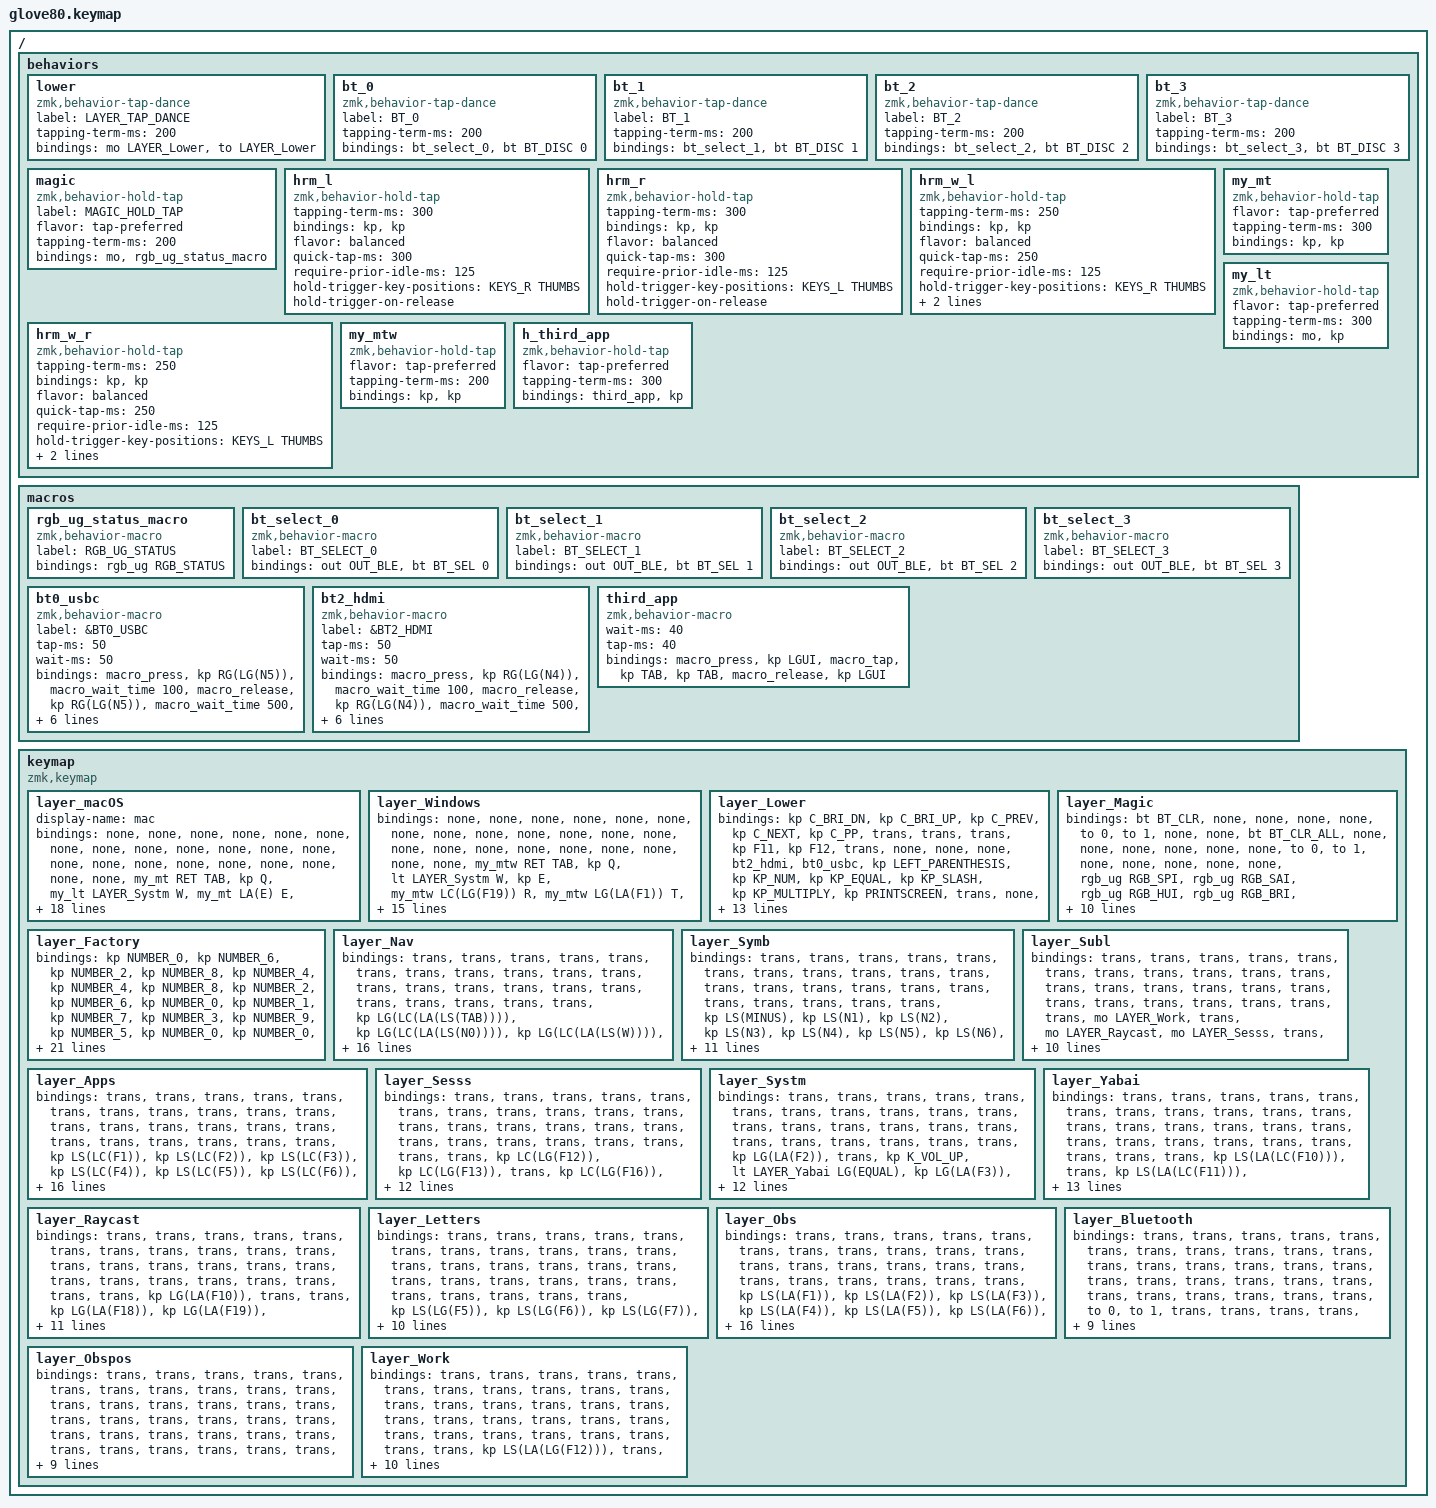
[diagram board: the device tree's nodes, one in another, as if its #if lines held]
/*
 * Copyright (c) 2020 The ZMK Contributors
 * Copyright (c) 2023 Innaworks Development Limited, trading as MoErgo
 *
 * SPDX-License-Identifier: MIT
 */


/* THIS FILE WAS GENERATED BY GLOVE80 LAYOUT EDITOR
 *
 * This file was generated automatically. You may or may not want to
 * edit it directly.
 */

#include <behaviors.dtsi>
/* Include all behavior includes needed */
#include <dt-bindings/zmk/outputs.h>
#include <dt-bindings/zmk/keys.h>
#include <dt-bindings/zmk/bt.h>
#include <dt-bindings/zmk/rgb.h>

/* On demand includes */


/* Automatically generated layer name #define */
#define LAYER_macOS 0
#define LAYER_Windows 1
#define LAYER_Lower 2
#define LAYER_Magic 3
#define LAYER_Factory 4
#define LAYER_Nav 5
#define LAYER_Symb 6
#define LAYER_Subl 7
#define LAYER_Apps 8
#define LAYER_Sesss 9
#define LAYER_Systm 10
#define LAYER_Yabai 11
#define LAYER_Raycast 12
#define LAYER_Letters 13
#define LAYER_Obs 14
#define LAYER_Bluetooth 15
#define LAYER_Obspos 16
#define LAYER_Work 17

/* To deal with the situation where there is no Lower layer, to keep &lower happy */
#ifndef LAYER_Lower
#define LAYER_Lower 0
#endif

/* Custom Device-tree */



/* Glove80 system behavior & macros */
/ {
    behaviors {
        // For the "layer" key, it'd nice to be able to use it as either a shift or a toggle.
        // Configure it as a tap dance, so the first tap (or hold) is a &mo and the second tap is a &to
        lower: lower {
            compatible = "zmk,behavior-tap-dance";
            label = "LAYER_TAP_DANCE";
            #binding-cells = <0>;
            tapping-term-ms = <200>;
            bindings = <&mo LAYER_Lower>, <&to LAYER_Lower>;
        };
    };
};

/ {
    macros {
        rgb_ug_status_macro: rgb_ug_status_macro {
            label = "RGB_UG_STATUS";
            compatible = "zmk,behavior-macro";
            #binding-cells = <0>;
            bindings
                = <&rgb_ug RGB_STATUS>;
        };
    };
};


/ {
#ifdef BT_DISC_CMD
    behaviors {
        bt_0: bt_0 {
            compatible = "zmk,behavior-tap-dance";
            label = "BT_0";
            #binding-cells = <0>;
            tapping-term-ms = <200>;
            bindings = <&bt_select_0>, <&bt BT_DISC 0>;
        };
        bt_1: bt_1 {
            compatible = "zmk,behavior-tap-dance";
            label = "BT_1";
            #binding-cells = <0>;
            tapping-term-ms = <200>;
            bindings = <&bt_select_1>, <&bt BT_DISC 1>;
        };
        bt_2: bt_2 {
            compatible = "zmk,behavior-tap-dance";
            label = "BT_2";
            #binding-cells = <0>;
            tapping-term-ms = <200>;
            bindings = <&bt_select_2>, <&bt BT_DISC 2>;
        };
        bt_3: bt_3 {
            compatible = "zmk,behavior-tap-dance";
            label = "BT_3";
            #binding-cells = <0>;
            tapping-term-ms = <200>;
            bindings = <&bt_select_3>, <&bt BT_DISC 3>;
        };
    };
    macros {
        bt_select_0: bt_select_0 {
            label = "BT_SELECT_0";
            compatible = "zmk,behavior-macro";
            #binding-cells = <0>;
            bindings
                = <&out OUT_BLE>,
                  <&bt BT_SEL 0>;
        };
        bt_select_1: bt_select_1 {
            label = "BT_SELECT_1";
            compatible = "zmk,behavior-macro";
            #binding-cells = <0>;
            bindings
                = <&out OUT_BLE>,
                  <&bt BT_SEL 1>;
        };
        bt_select_2: bt_select_2 {
            label = "BT_SELECT_2";
            compatible = "zmk,behavior-macro";
            #binding-cells = <0>;
            bindings
                = <&out OUT_BLE>,
                  <&bt BT_SEL 2>;
        };
        bt_select_3: bt_select_3 {
            label = "BT_SELECT_3";
            compatible = "zmk,behavior-macro";
            #binding-cells = <0>;
            bindings
                = <&out OUT_BLE>,
                  <&bt BT_SEL 3>;
        };
    };
#else
    macros {
        bt_0: bt_0 {
            label = "BT_0";
            compatible = "zmk,behavior-macro";
            #binding-cells = <0>;
            bindings
                = <&out OUT_BLE>,
                  <&bt BT_SEL 0>;
        };
        bt_1: bt_1 {
            label = "BT_1";
            compatible = "zmk,behavior-macro";
            #binding-cells = <0>;
            bindings
                = <&out OUT_BLE>,
                  <&bt BT_SEL 1>;
        };
        bt_2: bt_2 {
            label = "BT_2";
            compatible = "zmk,behavior-macro";
            #binding-cells = <0>;
            bindings
                = <&out OUT_BLE>,
                  <&bt BT_SEL 2>;
        };
        bt_3: bt_3 {
            label = "BT_3";
            compatible = "zmk,behavior-macro";
            #binding-cells = <0>;
            bindings
                = <&out OUT_BLE>,
                  <&bt BT_SEL 3>;
        };
    };
#endif
};

/ {
    behaviors {
        magic: magic {
            compatible = "zmk,behavior-hold-tap";
            label = "MAGIC_HOLD_TAP";
            #binding-cells = <2>;
            flavor = "tap-preferred";
            tapping-term-ms = <200>;
            bindings = <&mo>, <&rgb_ug_status_macro>;
        };
    };
};

/* #define for key positions */
#define POS_LH_T1 52
#define POS_LH_T2 53
#define POS_LH_T3 54
#define POS_LH_T4 69
#define POS_LH_T5 70
#define POS_LH_T6 71
#define POS_LH_C1R2 15
#define POS_LH_C1R3 27
#define POS_LH_C1R4 39
#define POS_LH_C1R5 51
#define POS_LH_C2R1 4
#define POS_LH_C2R2 14
#define POS_LH_C2R3 26
#define POS_LH_C2R4 38
#define POS_LH_C2R5 50
#define POS_LH_C2R6 68
#define POS_LH_C3R1 3
#define POS_LH_C3R2 13
#define POS_LH_C3R3 25
#define POS_LH_C3R4 37
#define POS_LH_C3R5 49
#define POS_LH_C3R6 67
#define POS_LH_C4R1 2
#define POS_LH_C4R2 12
#define POS_LH_C4R3 24
#define POS_LH_C4R4 36
#define POS_LH_C4R5 48
#define POS_LH_C4R6 66
#define POS_LH_C5R1 1
#define POS_LH_C5R2 11
#define POS_LH_C5R3 23
#define POS_LH_C5R4 35
#define POS_LH_C5R5 47
#define POS_LH_C5R6 65
#define POS_LH_C6R1 0
#define POS_LH_C6R2 10
#define POS_LH_C6R3 22
#define POS_LH_C6R4 34
#define POS_LH_C6R5 46
#define POS_LH_C6R6 64
#define POS_RH_T1 57
#define POS_RH_T2 56
#define POS_RH_T3 55
#define POS_RH_T4 74
#define POS_RH_T5 73
#define POS_RH_T6 72
#define POS_RH_C1R2 16
#define POS_RH_C1R3 28
#define POS_RH_C1R4 40
#define POS_RH_C1R5 58
#define POS_RH_C2R1 5
#define POS_RH_C2R2 17
#define POS_RH_C2R3 29
#define POS_RH_C2R4 41
#define POS_RH_C2R5 59
#define POS_RH_C2R6 75
#define POS_RH_C3R1 6
#define POS_RH_C3R2 18
#define POS_RH_C3R3 30
#define POS_RH_C3R4 42
#define POS_RH_C3R5 60
#define POS_RH_C3R6 76
#define POS_RH_C4R1 7
#define POS_RH_C4R2 19
#define POS_RH_C4R3 31
#define POS_RH_C4R4 43
#define POS_RH_C4R5 61
#define POS_RH_C4R6 77
#define POS_RH_C5R1 8
#define POS_RH_C5R2 20
#define POS_RH_C5R3 32
#define POS_RH_C5R4 44
#define POS_RH_C5R5 62
#define POS_RH_C5R6 78
#define POS_RH_C6R1 9
#define POS_RH_C6R2 21
#define POS_RH_C6R3 33
#define POS_RH_C6R4 45
#define POS_RH_C6R5 63
#define POS_RH_C6R6 79

#define KEYS_L 22 23 24 25 26 27 34 35 36 37 38 39 46 47 48 49 50 51
#define KEYS_R 28 29 30 31 32 33 40 41 42 43 44 45 58 59 60 61 62 63
#define THUMBS 69 70 73 74

/* Custom Defined Behaviors */
/ {
    macros {
        bt0_usbc: bt0_usbc {
            label = "&BT0_USBC";
            compatible = "zmk,behavior-macro";
            #binding-cells = <0>;
            tap-ms = <50>;
            wait-ms = <50>;
            bindings
                /* switch mouse */
                = <&macro_press>
                , <&kp RG(LG(N5))>
                , <&macro_wait_time 100>
                , <&macro_release>
                , <&kp RG(LG(N5))>
                , <&macro_wait_time 500>
                /* switch input source monitor */
                , <&macro_press>
                , <&kp LC(LA(LS(LG(N5))))>
                , <&macro_release>
                , <&kp LC(LA(LS(LG(N5))))>
                , <&macro_wait_time 50>
                /* pull github repos */
                , <&macro_press>
                , <&kp RG(LG(J))>
                , <&macro_release>
                , <&kp RG(LG(J))>
                , <&macro_wait_time 50>
                /* switch keyboard */
                , <&macro_press>
                , <&bt_0>
                , <&macro_release>
                , <&bt_0>;
        };
        bt2_hdmi: bt2_hdmi {
            label = "&BT2_HDMI";
            compatible = "zmk,behavior-macro";
            #binding-cells = <0>;
            tap-ms = <50>;
            wait-ms = <50>;
            bindings
                /* switch mouse */
                = <&macro_press>
                , <&kp RG(LG(N4))>
                , <&macro_wait_time 100>
                , <&macro_release>
                , <&kp RG(LG(N4))>
                , <&macro_wait_time 500>
                /* switch input source monitor */
                , <&macro_press>
                , <&kp LC(LA(LS(LG(N4))))>
                , <&macro_release>
                , <&kp LC(LA(LS(LG(N4))))>
                , <&macro_wait_time 50>
                /* pull github repos */
                , <&macro_press>
                , <&kp RG(LG(J))>
                , <&macro_release>
                , <&kp RG(LG(J))>
                , <&macro_wait_time 50>
                /* switch keyboard */
                , <&macro_press>
                , <&bt_2>
                , <&macro_release>
                , <&bt_2>;
        };
    };
};

/* Automatically generated macro definitions */
/ {
    macros {
        third_app: third_app {
            compatible = "zmk,behavior-macro";
            #binding-cells = <0>;
            wait-ms = <40>;
            tap-ms = <40>;
            bindings
                = <&macro_press &kp LGUI>
                , <&macro_tap &kp TAB &kp TAB>
                , <&macro_release &kp LGUI>
                ;
        };

    };
};

/* Automatically generated behavior definitions */
/ {
    behaviors {
        // Timeless home-row mods, adapted from the Toucan keymap.
        hrm_l: hrm_l {
            compatible = "zmk,behavior-hold-tap";
            #binding-cells = <2>;
            tapping-term-ms = <300>;
            bindings = <&kp>, <&kp>;
            flavor = "balanced";
            quick-tap-ms = <300>;
            require-prior-idle-ms = <125>;
            hold-trigger-key-positions = <KEYS_R THUMBS>;
            hold-trigger-on-release;
        };

        hrm_r: hrm_r {
            compatible = "zmk,behavior-hold-tap";
            #binding-cells = <2>;
            tapping-term-ms = <300>;
            bindings = <&kp>, <&kp>;
            flavor = "balanced";
            quick-tap-ms = <300>;
            require-prior-idle-ms = <125>;
            hold-trigger-key-positions = <KEYS_L THUMBS>;
            hold-trigger-on-release;
        };

        hrm_w_l: hrm_w_l {
            compatible = "zmk,behavior-hold-tap";
            #binding-cells = <2>;
            tapping-term-ms = <250>;
            bindings = <&kp>, <&kp>;
            flavor = "balanced";
            quick-tap-ms = <250>;
            require-prior-idle-ms = <125>;
            hold-trigger-key-positions = <KEYS_R THUMBS>;
            hold-trigger-on-release;
            retro-tap;
        };

        hrm_w_r: hrm_w_r {
            compatible = "zmk,behavior-hold-tap";
            #binding-cells = <2>;
            tapping-term-ms = <250>;
            bindings = <&kp>, <&kp>;
            flavor = "balanced";
            quick-tap-ms = <250>;
            require-prior-idle-ms = <125>;
            hold-trigger-key-positions = <KEYS_L THUMBS>;
            hold-trigger-on-release;
            retro-tap;
        };

        my_mt: my_mt {
            compatible = "zmk,behavior-hold-tap";
            #binding-cells = <2>;
            flavor = "tap-preferred";
            tapping-term-ms = <300>;
            bindings = <&kp>, <&kp>;
        };

        my_lt: my_lt {
            compatible = "zmk,behavior-hold-tap";
            #binding-cells = <2>;
            flavor = "tap-preferred";
            tapping-term-ms = <300>;
            bindings = <&mo>, <&kp>;
        };

        my_mtw: my_mtw {
            compatible = "zmk,behavior-hold-tap";
            #binding-cells = <2>;
            flavor = "tap-preferred";
            tapping-term-ms = <200>;
            bindings = <&kp>, <&kp>;
        };

        h_third_app: h_third_app {
            compatible = "zmk,behavior-hold-tap";
            #binding-cells = <2>;
            flavor = "tap-preferred";
            tapping-term-ms = <300>;
            bindings = <&third_app>, <&kp>;
        };

        /* symbl: symbl { */
        /*     compatible = "zmk,behavior-hold-tap"; */
        /*     #binding-cells = <2>; */
        /*     flavor = "tap-preferred"; */
        /*     tapping-term-ms = <300>; */
        /*     bindings = <&mo>, <&kp>; */
        /*     display-name = "Symbol-Layer"; */
        /* }; */

    };
};

/* Automatically generated combos definitions */


/* Automatically generated keymap */
/ {
    keymap {
        compatible = "zmk,keymap";


        layer_macOS {
            display-name = "mac";
            bindings = <
//    ┌────────────────────────┬────────────────────┬────────────────────────┬──────────────────┬──────────────────────────┐                                                                                                                     ┌─────────────────────────┬───────────────┬────────────────────────────────────┬───────────────┬─────┐
//    │                        │                    │                        │                  │                          │                                                                                                                     │                         │               │                                    │               │     │
//    ├────────────────────────┼────────────────────┼────────────────────────┼──────────────────┼──────────────────────────┼─────────────────────────┐                                                                        ┌──────────────────┼─────────────────────────┼───────────────┼────────────────────────────────────┼───────────────┼─────┤
//    │                        │                    │                        │                  │                          │                         │                                                                        │                  │                         │               │                                    │               │     │
//    ├────────────────────────┼────────────────────┼────────────────────────┼──────────────────┼──────────────────────────┼─────────────────────────┤                                                                        ├──────────────────┼─────────────────────────┼───────────────┼────────────────────────────────────┼───────────────┼─────┤
//    │     &my_mt ent tab     │         Q          │ &my_lt laltYER_Systm W │ &my_mt lalt(E) E │ &my_mt lctl(lgui(f19)) R │ &my_mt lgui(lalt(f1)) T │                                                                        │        Y         │    &my_mt lgui(Z) U     │       I       │ &my_mt lgui(lctl(lalt(lsft(Z)))) O │       P       │  \  │
//    ├────────────────────────┼────────────────────┼────────────────────────┼──────────────────┼──────────────────────────┼─────────────────────────┤                                                                        ├──────────────────┼─────────────────────────┼───────────────┼────────────────────────────────────┼───────────────┼─────┤
//    │   lt laltYER_Nav esc   │   &hrm_l lctl A    │     &hrm_l lsft S      │  &hrm_l lalt D   │      &hrm_l lgui F       │    &my_mt lctl(Z) G     │                                                                        │ &h_third_app 0 H │      &hrm_r rgui J      │ &hrm_r ralt K │           &hrm_r rsft L            │ &hrm_r rctl ; │  '  │
//    ├────────────────────────┼────────────────────┼────────────────────────┼──────────────────┼──────────────────────────┼─────────────────────────┼──────────────────────┬─────┬─────┐   ┌─────┬─────┬─────────────────────┼──────────────────┼─────────────────────────┼───────────────┼────────────────────────────────────┼───────────────┼─────┤
//    │                        │ &my_mt lgui(tab) Z │    &my_mt lgui(`) X    │ &my_mt lgui(C) C │     &my_mt lgui(V) V     │ &my_mt lgui(lalt(f8)) B │                      │     │     │   │     │     │                     │ &my_mt lalt(N) N │ &my_mt lgui(lalt(f9)) M │       ,       │ &my_mt lgui(lctl(lalt(lsft(6)))) . │       /       │     │
//    ├────────────────────────┼────────────────────┼────────────────────────┼──────────────────┼──────────────────────────┼─────────────────────────┼──────────────────────┼─────┼─────┤   ├─────┼─────┼─────────────────────┼──────────────────┼─────────────────────────┼───────────────┼────────────────────────────────────┼───────────────┼─────┤
//    │ &magic laltYER_Magic 0 │                    │                        │                  │                          │                         │ lt laltYER_Symb bspc │ spc │     │   │     │ spc │ lt laltYER_Subl ent │                  │                         │               │                                    │               │     │
//    └────────────────────────┴────────────────────┴────────────────────────┴──────────────────┴──────────────────────────┘                         └──────────────────────┴─────┴─────┘   └─────┴─────┴─────────────────────┘                  └─────────────────────────┴───────────────┴────────────────────────────────────┴───────────────┴─────┘
  &none                  &none              &none                  &none            &none                                                                                                                                                  &none                 &none           &none                          &none               &none
  &none                  &none              &none                  &none            &none                  &none                                                                                                        &none              &none                 &none           &none                          &none               &none
  &my_mt RET TAB         &kp Q              &my_lt LAYER_Systm W   &my_mt LA(E) E   &my_mt LC(LG(F19)) R   &my_mt LG(LA(F1)) T                                                                                          &kp Y              &my_mt LG(Z) U        &kp I           &my_mt LG(LC(LA(LS(Z)))) O     &kp P               &kp BSLH
  &lt LAYER_Nav ESC      &hrm_l LCTRL A     &hrm_l LSHFT S         &hrm_l LALT D    &hrm_l LGUI F          &my_mt LC(Z) G                                                                                               &h_third_app 0 H   &hrm_r RGUI J         &hrm_r RALT K   &hrm_r RSHFT L                 &hrm_r RCTRL SEMI   &kp SQT
  &none                  &my_mt LG(TAB) Z   &my_mt LG(GRAVE) X     &my_mt LG(C) C   &my_mt LG(V) V         &my_mt LG(LA(F8)) B   &none                 &none       &none       &none   &none       &none                &my_mt LA(N) N     &my_mt LG(LA(F9)) M   &kp COMMA       &my_mt LG(LC(LA(LS(6)))) DOT   &kp FSLH            &none
  &magic LAYER_Magic 0   &none              &none                  &none            &none                                        &lt LAYER_Symb BSPC   &kp SPACE   &none       &none   &kp SPACE   &lt LAYER_Subl RET                      &none                 &none           &none                          &none               &none
            >;
        };


        layer_Windows {
            bindings = <
//    ┌────────────────────────┬────────────────────────────────┬────────────────────────────────┬───────────────────┬───────────────────────────┐                                                                                                         ┌──────────────────┬─────────────────┬─────────────────┬─────────────────┬─────┐
//    │                        │                                │                                │                   │                           │                                                                                                         │                  │                 │                 │                 │     │
//    ├────────────────────────┼────────────────────────────────┼────────────────────────────────┼───────────────────┼───────────────────────────┼──────────────────────────┐                                                                        ┌─────┼──────────────────┼─────────────────┼─────────────────┼─────────────────┼─────┤
//    │                        │                                │                                │                   │                           │                          │                                                                        │     │                  │                 │                 │                 │     │
//    ├────────────────────────┼────────────────────────────────┼────────────────────────────────┼───────────────────┼───────────────────────────┼──────────────────────────┤                                                                        ├─────┼──────────────────┼─────────────────┼─────────────────┼─────────────────┼─────┤
//    │    &my_mtw ent tab     │               Q                │       lt laltYER_Systm W       │         E         │ &my_mtw lctl(lgui(f19)) R │ &my_mtw lgui(lalt(f1)) T │                                                                        │  Y  │ &my_mt lctl(Z) U │        I        │        O        │        P        │  \  │
//    ├────────────────────────┼────────────────────────────────┼────────────────────────────────┼───────────────────┼───────────────────────────┼──────────────────────────┤                                                                        ├─────┼──────────────────┼─────────────────┼─────────────────┼─────────────────┼─────┤
//    │   lt laltYER_Nav esc   │        &hrm_w_l lctl A         │        &hrm_w_l lsft S         │  &hrm_w_l lgui D  │      &hrm_w_l lalt F      │            G             │                                                                        │  H  │ &hrm_w_r ralt J  │ &hrm_w_r rgui K │ &hrm_w_r rsft L │ &hrm_w_r rctl ; │  '  │
//    ├────────────────────────┼────────────────────────────────┼────────────────────────────────┼───────────────────┼───────────────────────────┼──────────────────────────┼──────────────────────┬─────┬─────┐   ┌─────┬─────┬─────────────────────┼─────┼──────────────────┼─────────────────┼─────────────────┼─────────────────┼─────┤
//    │                        │ &my_mtw lsft(lalt(lgui(f6))) Z │ &my_mtw lsft(lalt(lgui(f7))) X │ &my_mtw lctl(C) C │     &my_mtw lctl(V) V     │            B             │                      │     │     │   │     │     │                     │  N  │        M         │        ,        │        .        │        /        │     │
//    ├────────────────────────┼────────────────────────────────┼────────────────────────────────┼───────────────────┼───────────────────────────┼──────────────────────────┼──────────────────────┼─────┼─────┤   ├─────┼─────┼─────────────────────┼─────┼──────────────────┼─────────────────┼─────────────────┼─────────────────┼─────┤
//    │ &magic laltYER_Magic 0 │                                │                                │                   │                           │                          │ lt laltYER_Symb bspc │ spc │     │   │     │ spc │ lt laltYER_Subl ent │     │                  │                 │                 │                 │     │
//    └────────────────────────┴────────────────────────────────┴────────────────────────────────┴───────────────────┴───────────────────────────┘                          └──────────────────────┴─────┴─────┘   └─────┴─────┴─────────────────────┘     └──────────────────┴─────────────────┴─────────────────┴─────────────────┴─────┘
  &none                  &none                      &none                      &none             &none                                                                                                                                         &none             &none             &none              &none                 &none
  &none                  &none                      &none                      &none             &none                   &none                                                                                                         &none   &none             &none             &none              &none                 &none
  &my_mtw RET TAB        &kp Q                      &lt LAYER_Systm W          &kp E             &my_mtw LC(LG(F19)) R   &my_mtw LG(LA(F1)) T                                                                                          &kp Y   &my_mt LC(Z) U    &kp I             &kp O              &kp P                 &kp BSLH
  &lt LAYER_Nav ESC      &hrm_w_l LCTRL A           &hrm_w_l LSHFT S           &hrm_w_l LGUI D   &hrm_w_l LALT F         &kp G                                                                                                         &kp H   &hrm_w_r RALT J   &hrm_w_r RGUI K   &hrm_w_r RSHFT L   &hrm_w_r RCTRL SEMI   &kp SQT
  &none                  &my_mtw LS(LA(LG(F6))) Z   &my_mtw LS(LA(LG(F7))) X   &my_mtw LC(C) C   &my_mtw LC(V) V         &kp B                  &none                 &none       &none       &none   &none       &none                &kp N   &kp M             &kp COMMA         &kp DOT            &kp FSLH              &none
  &magic LAYER_Magic 0   &none                      &none                      &none             &none                                          &lt LAYER_Symb BSPC   &kp SPACE   &none       &none   &kp SPACE   &lt LAYER_Subl RET           &none             &none             &none              &none                 &none
            >;
        };

        layer_Lower {
            bindings = <
//    ┌────────────────────────┬──────┬──────┬──────┬───────────┐                                                       ┌──────┬──────┬──────┬──────┬──────┐
//    │          bri-          │ bri+ │ prev │ next │   play    │                                                       │      │      │      │ f11  │ f12  │
//    ├────────────────────────┼──────┼──────┼──────┼───────────┼───────────┐                                       ┌───┼──────┼──────┼──────┼──────┼──────┤
//    │                        │      │      │      │ &bt2_hdmi │ &bt0_usbc │                                       │ ( │ nlck │ kp_= │ kp_/ │ kp_* │ pscr │
//    ├────────────────────────┼──────┼──────┼──────┼───────────┼───────────┤                                       ├───┼──────┼──────┼──────┼──────┼──────┤
//    │                        │      │      │  up  │           │    end    │                                       │ ) │  7   │  8   │  9   │ kp_- │ slck │
//    ├────────────────────────┼──────┼──────┼──────┼───────────┼───────────┤                                       ├───┼──────┼──────┼──────┼──────┼──────┤
//    │                        │      │ left │ down │   rght    │    ent    │                                       │ % │  4   │  5   │  6   │ kp_+ │      │
//    ├────────────────────────┼──────┼──────┼──────┼───────────┼───────────┼─────┬─────┬─────┐   ┌─────┬─────┬─────┼───┼──────┼──────┼──────┼──────┼──────┤
//    │                        │ app  │      │      │           │   pgdn    │     │     │     │   │     │     │     │ , │  1   │  2   │  3   │ ent  │      │
//    ├────────────────────────┼──────┼──────┼──────┼───────────┼───────────┼─────┼─────┼─────┤   ├─────┼─────┼─────┼───┼──────┼──────┼──────┼──────┼──────┤
//    │ &magic laltYER_Magic 0 │ caps │ ins  │ f11  │    f12    │           │     │     │     │   │     │     │     │   │  0   │  0   │ kp_. │ ent  │      │
//    └────────────────────────┴──────┴──────┴──────┴───────────┘           └─────┴─────┴─────┘   └─────┴─────┴─────┘   └──────┴──────┴──────┴──────┴──────┘
  &kp C_BRI_DN           &kp C_BRI_UP   &kp C_PREV       &kp C_NEXT       &kp C_PP                                                                                                  &trans       &trans         &trans         &kp F11           &kp F12
  &trans                 &none          &none            &none            &bt2_hdmi   &bt0_usbc                                                             &kp LEFT_PARENTHESIS    &kp KP_NUM   &kp KP_EQUAL   &kp KP_SLASH   &kp KP_MULTIPLY   &kp PRINTSCREEN
  &trans                 &none          &none            &kp UP_ARROW     &none       &kp END                                                               &kp RIGHT_PARENTHESIS   &kp KP_N7    &kp KP_N8      &kp KP_N9      &kp KP_MINUS      &kp SCROLLLOCK
  &trans                 &none          &kp LEFT_ARROW   &kp DOWN_ARROW   &kp RIGHT   &kp RET                                                               &kp PERCENT             &kp KP_N4    &kp KP_N5      &kp KP_N6      &kp KP_PLUS       &none
  &trans                 &kp K_APP      &trans           &trans           &trans      &kp PG_DN   &trans   &trans   &trans       &trans   &trans   &trans   &kp COMMA               &kp KP_N1    &kp KP_N2      &kp KP_N3      &kp KP_ENTER      &trans
  &magic LAYER_Magic 0   &kp CAPS       &kp INS          &kp F11          &kp F12                 &trans   &trans   &trans       &trans   &trans   &trans                           &kp KP_N0    &kp KP_N0      &kp KP_DOT     &kp KP_ENTER      &trans
            >;
        };

        layer_Magic {
            bindings = <
//    ┌────────────┬─────────┬─────────┬─────────┬─────────┐                                                                 ┌──────┬──────┬─────┬─────┬────────────┐
//    │   bt_clr   │         │         │         │         │                                                                 │ to 0 │ to 1 │     │     │ bt_clr_ALL │
//    ├────────────┼─────────┼─────────┼─────────┼─────────┼─────────┐                                                ┌──────┼──────┼──────┼─────┼─────┼────────────┤
//    │            │         │         │         │         │         │                                                │ to 0 │ to 1 │      │     │     │            │
//    ├────────────┼─────────┼─────────┼─────────┼─────────┼─────────┤                                                ├──────┼──────┼──────┼─────┼─────┼────────────┤
//    │            │ ug_ sp+ │ ug_ sa+ │ ug_ hu+ │ ug_ br+ │ ug_ tog │                                                │      │      │      │     │     │            │
//    ├────────────┼─────────┼─────────┼─────────┼─────────┼─────────┤                                                ├──────┼──────┼──────┼─────┼─────┼────────────┤
//    │    boot    │ ug_ sp- │ ug_ sa- │ ug_ hu- │ ug_ br- │ ug_ eff │                                                │      │      │      │     │     │    boot    │
//    ├────────────┼─────────┼─────────┼─────────┼─────────┼─────────┼───────┬───────┬──────────┐   ┌─────┬─────┬─────┼──────┼──────┼──────┼─────┼─────┼────────────┤
//    │ &sys_reset │         │         │         │         │         │ &bt_2 │ &bt_3 │          │   │     │     │     │      │      │      │     │     │ &sys_reset │
//    ├────────────┼─────────┼─────────┼─────────┼─────────┼─────────┼───────┼───────┼──────────┤   ├─────┼─────┼─────┼──────┼──────┼──────┼─────┼─────┼────────────┤
//    │            │         │         │         │         │         │ &bt_0 │ &bt_1 │ out_ usb │   │     │     │     │      │      │      │     │     │    to 3    │
//    └────────────┴─────────┴─────────┴─────────┴─────────┘         └───────┴───────┴──────────┘   └─────┴─────┴─────┘      └──────┴──────┴─────┴─────┴────────────┘
  &bt BT_CLR    &none             &none             &none             &none                                                                                                  &to 0   &to 1   &none   &none   &bt BT_CLR_ALL
  &none         &none             &none             &none             &none             &none                                                                        &to 0   &to 1   &none   &none   &none   &none
  &none         &rgb_ug RGB_SPI   &rgb_ug RGB_SAI   &rgb_ug RGB_HUI   &rgb_ug RGB_BRI   &rgb_ug RGB_TOG                                                              &none   &none   &none   &none   &none   &none
  &bootloader   &rgb_ug RGB_SPD   &rgb_ug RGB_SAD   &rgb_ug RGB_HUD   &rgb_ug RGB_BRD   &rgb_ug RGB_EFF                                                              &none   &none   &none   &none   &none   &bootloader
  &sys_reset    &none             &none             &none             &none             &none             &bt_2   &bt_3   &none              &none   &none   &none   &none   &none   &none   &none   &none   &sys_reset
  &none         &none             &none             &none             &none                               &bt_0   &bt_1   &out OUT_USB       &none   &none   &none           &none   &none   &none   &none   &to 3
            >;
        };

        layer_Factory {
            bindings = <
//    ┌───┬───┬───┬───┬───┐                                   ┌───┬───┬───┬───┬───┐
//    │ 0 │ 6 │ 2 │ 8 │ 4 │                                   │ 4 │ 8 │ 2 │ 6 │ 0 │
//    ├───┼───┼───┼───┼───┼───┐                           ┌───┼───┼───┼───┼───┼───┤
//    │ 1 │ 7 │ 3 │ 9 │ 5 │ 0 │                           │ 0 │ 5 │ 9 │ 3 │ 7 │ 1 │
//    ├───┼───┼───┼───┼───┼───┤                           ├───┼───┼───┼───┼───┼───┤
//    │ 2 │ 8 │ 4 │ 0 │ 6 │ 1 │                           │ 1 │ 6 │ 0 │ 4 │ 8 │ 2 │
//    ├───┼───┼───┼───┼───┼───┤                           ├───┼───┼───┼───┼───┼───┤
//    │ 3 │ 9 │ 5 │ 1 │ 7 │ 2 │                           │ 2 │ 7 │ 1 │ 5 │ 9 │ 3 │
//    ├───┼───┼───┼───┼───┼───┼───┬───┬───┐   ┌───┬───┬───┼───┼───┼───┼───┼───┼───┤
//    │ 4 │ 0 │ 6 │ 2 │ 8 │ 3 │ 4 │ 5 │ 6 │   │ 6 │ 5 │ 4 │ 3 │ 8 │ 2 │ 6 │ 0 │ 4 │
//    ├───┼───┼───┼───┼───┼───┼───┼───┼───┤   ├───┼───┼───┼───┼───┼───┼───┼───┼───┤
//    │ 5 │ 1 │ 7 │ 3 │ 9 │   │ 7 │ 8 │ 9 │   │ 9 │ 8 │ 7 │   │ 9 │ 3 │ 7 │ 1 │ 5 │
//    └───┴───┴───┴───┴───┘   └───┴───┴───┘   └───┴───┴───┘   └───┴───┴───┴───┴───┘
  &kp NUMBER_0   &kp NUMBER_6   &kp NUMBER_2   &kp NUMBER_8   &kp NUMBER_4                                                                                                                               &kp NUMBER_4   &kp NUMBER_8   &kp NUMBER_2   &kp NUMBER_6   &kp NUMBER_0
  &kp NUMBER_1   &kp NUMBER_7   &kp NUMBER_3   &kp NUMBER_9   &kp NUMBER_5   &kp NUMBER_0                                                                                                 &kp NUMBER_0   &kp NUMBER_5   &kp NUMBER_9   &kp NUMBER_3   &kp NUMBER_7   &kp NUMBER_1
  &kp NUMBER_2   &kp NUMBER_8   &kp NUMBER_4   &kp NUMBER_0   &kp NUMBER_6   &kp NUMBER_1                                                                                                 &kp NUMBER_1   &kp NUMBER_6   &kp NUMBER_0   &kp NUMBER_4   &kp NUMBER_8   &kp NUMBER_2
  &kp NUMBER_3   &kp NUMBER_9   &kp NUMBER_5   &kp NUMBER_1   &kp NUMBER_7   &kp NUMBER_2                                                                                                 &kp NUMBER_2   &kp NUMBER_7   &kp NUMBER_1   &kp NUMBER_5   &kp NUMBER_9   &kp NUMBER_3
  &kp NUMBER_4   &kp NUMBER_0   &kp NUMBER_6   &kp NUMBER_2   &kp NUMBER_8   &kp NUMBER_3   &kp NUMBER_4   &kp NUMBER_5   &kp NUMBER_6       &kp NUMBER_6   &kp NUMBER_5   &kp NUMBER_4   &kp NUMBER_3   &kp NUMBER_8   &kp NUMBER_2   &kp NUMBER_6   &kp NUMBER_0   &kp NUMBER_4
  &kp NUMBER_5   &kp NUMBER_1   &kp NUMBER_7   &kp NUMBER_3   &kp NUMBER_9                  &kp NUMBER_7   &kp NUMBER_8   &kp NUMBER_9       &kp NUMBER_9   &kp NUMBER_8   &kp NUMBER_7                  &kp NUMBER_9   &kp NUMBER_3   &kp NUMBER_7   &kp NUMBER_1   &kp NUMBER_5
            >;
        };

        layer_Nav {
            bindings = <
//    ┌─────────────────────────────┬───────────────────────────┬───────────────────────────┬───────────────────────────┬─────────┐                                                                                       ┌──────────────────┬────────────────┬──────────────────┬───────────────────────────┬─────┐
//    │                             │                           │                           │                           │         │                                                                                       │                  │                │                  │                           │     │
//    ├─────────────────────────────┼───────────────────────────┼───────────────────────────┼───────────────────────────┼─────────┼───────────────────────────┐                                        ┌──────────────────┼──────────────────┼────────────────┼──────────────────┼───────────────────────────┼─────┤
//    │                             │                           │                           │                           │         │                           │                                        │                  │                  │                │                  │                           │     │
//    ├─────────────────────────────┼───────────────────────────┼───────────────────────────┼───────────────────────────┼─────────┼───────────────────────────┤                                        ├──────────────────┼──────────────────┼────────────────┼──────────────────┼───────────────────────────┼─────┤
//    │ lgui(lctl(lalt(lsft(tab)))) │ lgui(lctl(lalt(lsft(0)))) │ lgui(lctl(lalt(lsft(W)))) │ lgui(lctl(lalt(lsft(D)))) │         │ lgui(lctl(lalt(lsft(T)))) │                                        │ lalt(lsft(left)) │ lalt(lsft(down)) │ lalt(lsft(up)) │ lalt(lsft(rght)) │                           │     │
//    ├─────────────────────────────┼───────────────────────────┼───────────────────────────┼───────────────────────────┼─────────┼───────────────────────────┤                                        ├──────────────────┼──────────────────┼────────────────┼──────────────────┼───────────────────────────┼─────┤
//    │                             │ lgui(lctl(lalt(lsft(=)))) │ lgui(lctl(lalt(lsft(9)))) │          lgui([)          │ lgui(]) │ lgui(lctl(lalt(lsft(G)))) │                                        │       left       │       down       │       up       │       rght       │ lgui(lctl(lalt(lsft(;)))) │     │
//    ├─────────────────────────────┼───────────────────────────┼───────────────────────────┼───────────────────────────┼─────────┼───────────────────────────┼─────┬─────┬─────┐   ┌─────┬─────┬──────┼──────────────────┼──────────────────┼────────────────┼──────────────────┼───────────────────────────┼─────┤
//    │                             │                           │                           │                           │         │ lgui(lctl(lalt(lsft(B)))) │     │     │     │   │     │     │      │                  │                  │                │                  │                           │     │
//    ├─────────────────────────────┼───────────────────────────┼───────────────────────────┼───────────────────────────┼─────────┼───────────────────────────┼─────┼─────┼─────┤   ├─────┼─────┼──────┼──────────────────┼──────────────────┼────────────────┼──────────────────┼───────────────────────────┼─────┤
//    │                             │                           │                           │                           │         │                           │     │     │     │   │     │     │ caps │                  │                  │                │                  │                           │     │
//    └─────────────────────────────┴───────────────────────────┴───────────────────────────┴───────────────────────────┴─────────┘                           └─────┴─────┴─────┘   └─────┴─────┴──────┘                  └──────────────────┴────────────────┴──────────────────┴───────────────────────────┴─────┘
  &trans                    &trans                      &trans                   &trans                  &trans                                                                                                                &trans             &trans           &trans              &trans                     &trans
  &trans                    &trans                      &trans                   &trans                  &trans         &trans                                                                              &trans             &trans             &trans           &trans              &trans                     &trans
  &kp LG(LC(LA(LS(TAB))))   &kp LG(LC(LA(LS(N0))))      &kp LG(LC(LA(LS(W))))    &kp LG(LC(LA(LS(D))))   &trans         &kp LG(LC(LA(LS(T))))                                                               &kp LA(LS(LEFT))   &kp LA(LS(DOWN))   &kp LA(LS(UP))   &kp LA(LS(RIGHT))   &trans                     &trans
  &trans                    &kp LG(LC(LA(LS(EQUAL))))   &kp LG(LC(LA(LS(N9))))   &kp LG(LBKT)            &kp LG(RBKT)   &kp LG(LC(LA(LS(G))))                                                               &kp LEFT           &kp DOWN           &kp UP           &kp RIGHT           &kp LG(LC(LA(LS(SEMI))))   &trans
  &trans                    &trans                      &trans                   &trans                  &trans         &kp LG(LC(LA(LS(B))))   &trans   &trans   &trans       &trans   &trans   &trans     &trans             &trans             &trans           &trans              &trans                     &trans
  &trans                    &trans                      &trans                   &trans                  &trans                                 &trans   &trans   &trans       &trans   &trans   &kp CAPS                      &trans             &trans           &trans              &trans                     &trans
            >;
        };

        layer_Symb {
            bindings = <
//    ┌─────────┬─────────┬─────────┬─────────┬─────────┐                                                           ┌─────────┬─────────┬─────────┬─────────┬─────┐
//    │         │         │         │         │         │                                                           │         │         │         │         │     │
//    ├─────────┼─────────┼─────────┼─────────┼─────────┼─────────┐                                       ┌─────────┼─────────┼─────────┼─────────┼─────────┼─────┤
//    │         │         │         │         │         │         │                                       │         │         │         │         │         │     │
//    ├─────────┼─────────┼─────────┼─────────┼─────────┼─────────┤                                       ├─────────┼─────────┼─────────┼─────────┼─────────┼─────┤
//    │ lsft(-) │ lsft(1) │ lsft(2) │ lsft(3) │ lsft(4) │ lsft(5) │                                       │ lsft(6) │ lsft(7) │ lsft(8) │ lsft(9) │ lsft(0) │  -  │
//    ├─────────┼─────────┼─────────┼─────────┼─────────┼─────────┤                                       ├─────────┼─────────┼─────────┼─────────┼─────────┼─────┤
//    │ lsft(`) │    1    │    2    │    3    │    4    │    5    │                                       │    6    │    7    │    8    │    9    │    0    │  `  │
//    ├─────────┼─────────┼─────────┼─────────┼─────────┼─────────┼─────┬─────┬─────┐   ┌─────┬─────┬─────┼─────────┼─────────┼─────────┼─────────┼─────────┼─────┤
//    │ lsft(=) │ lsft(,) │ lsft(.) │ lsft(/) │    [    │    ]    │     │     │     │   │     │     │     │ lsft([) │ lsft(]) │    ,    │    .    │    /    │  =  │
//    ├─────────┼─────────┼─────────┼─────────┼─────────┼─────────┼─────┼─────┼─────┤   ├─────┼─────┼─────┼─────────┼─────────┼─────────┼─────────┼─────────┼─────┤
//    │         │         │         │         │         │         │     │     │     │   │     │     │     │         │         │         │         │         │     │
//    └─────────┴─────────┴─────────┴─────────┴─────────┘         └─────┴─────┴─────┘   └─────┴─────┴─────┘         └─────────┴─────────┴─────────┴─────────┴─────┘
  &trans          &trans          &trans        &trans         &trans                                                                                             &trans         &trans       &trans       &trans       &trans
  &trans          &trans          &trans        &trans         &trans       &trans                                                                 &trans         &trans         &trans       &trans       &trans       &trans
  &kp LS(MINUS)   &kp LS(N1)      &kp LS(N2)    &kp LS(N3)     &kp LS(N4)   &kp LS(N5)                                                             &kp LS(N6)     &kp LS(N7)     &kp LS(N8)   &kp LS(N9)   &kp LS(N0)   &kp MINUS
  &kp LS(GRAVE)   &kp N1          &kp N2        &kp N3         &kp N4       &kp N5                                                                 &kp N6         &kp N7         &kp N8       &kp N9       &kp N0       &kp GRAVE
  &kp LS(EQUAL)   &kp LS(COMMA)   &kp LS(DOT)   &kp LS(FSLH)   &kp LBKT     &kp RBKT     &trans   &trans   &trans       &trans   &trans   &trans   &kp LS(LBKT)   &kp LS(RBKT)   &kp COMMA    &kp DOT      &kp FSLH     &kp EQUAL
  &trans          &trans          &trans        &trans         &trans                    &trans   &trans   &trans       &trans   &trans   &trans                  &trans         &trans       &trans       &trans       &trans
            >;
        };

        layer_Subl {
            bindings = <
//    ┌─────┬─────┬────────────────────┬─────┬────────────────────┐                                                                                ┌─────┬─────┬────────────────┬─────┬─────┐
//    │     │     │                    │     │                    │                                                                                │     │     │                │     │     │
//    ├─────┼─────┼────────────────────┼─────┼────────────────────┼──────────────────────┐                                                   ┌─────┼─────┼─────┼────────────────┼─────┼─────┤
//    │     │     │                    │     │                    │                      │                                                   │     │     │     │                │     │     │
//    ├─────┼─────┼────────────────────┼─────┼────────────────────┼──────────────────────┤                                                   ├─────┼─────┼─────┼────────────────┼─────┼─────┤
//    │     │     │  mo laltYER_Work   │     │ mo laltYER_Raycast │   mo laltYER_Sesss   │                                                   │     │     │     │ mo laltYER_Obs │     │     │
//    ├─────┼─────┼────────────────────┼─────┼────────────────────┼──────────────────────┤                                                   ├─────┼─────┼─────┼────────────────┼─────┼─────┤
//    │     │     │ mo laltYER_Letters │     │                    │                      │                                                   │     │     │     │                │     │     │
//    ├─────┼─────┼────────────────────┼─────┼────────────────────┼──────────────────────┼─────────────────┬─────┬─────┐   ┌─────┬─────┬─────┼─────┼─────┼─────┼────────────────┼─────┼─────┤
//    │     │     │                    │     │                    │ mo laltYER_Bluetooth │                 │     │     │   │     │     │     │     │     │     │                │     │     │
//    ├─────┼─────┼────────────────────┼─────┼────────────────────┼──────────────────────┼─────────────────┼─────┼─────┤   ├─────┼─────┼─────┼─────┼─────┼─────┼────────────────┼─────┼─────┤
//    │     │     │                    │     │                    │                      │ mo laltYER_Apps │     │     │   │     │     │     │     │     │     │                │     │     │
//    └─────┴─────┴────────────────────┴─────┴────────────────────┘                      └─────────────────┴─────┴─────┘   └─────┴─────┴─────┘     └─────┴─────┴────────────────┴─────┴─────┘
  &trans   &trans   &trans              &trans   &trans                                                                                                               &trans   &trans   &trans          &trans   &trans
  &trans   &trans   &trans              &trans   &trans              &trans                                                                                  &trans   &trans   &trans   &trans          &trans   &trans
  &trans   &trans   &mo LAYER_Work      &trans   &mo LAYER_Raycast   &mo LAYER_Sesss                                                                         &trans   &trans   &trans   &mo LAYER_Obs   &trans   &trans
  &trans   &trans   &mo LAYER_Letters   &trans   &trans              &trans                                                                                  &trans   &trans   &trans   &trans          &trans   &trans
  &trans   &trans   &trans              &trans   &trans              &mo LAYER_Bluetooth   &trans           &trans   &trans       &trans   &trans   &trans   &trans   &trans   &trans   &trans          &trans   &trans
  &trans   &trans   &trans              &trans   &trans                                    &mo LAYER_Apps   &trans   &trans       &trans   &trans   &trans            &trans   &trans   &trans          &trans   &trans
            >;
        };

        layer_Apps {
            bindings = <
//    ┌─────┬─────────────────┬─────────────────┬─────────────────┬─────────────────┐                                                                           ┌─────────────────┬─────────────────┬─────────────────┬─────────────────┬─────────────────┐
//    │     │                 │                 │                 │                 │                                                                           │                 │                 │                 │                 │                 │
//    ├─────┼─────────────────┼─────────────────┼─────────────────┼─────────────────┼─────────────────┐                                       ┌─────────────────┼─────────────────┼─────────────────┼─────────────────┼─────────────────┼─────────────────┤
//    │     │                 │                 │                 │                 │                 │                                       │                 │                 │                 │                 │                 │                 │
//    ├─────┼─────────────────┼─────────────────┼─────────────────┼─────────────────┼─────────────────┤                                       ├─────────────────┼─────────────────┼─────────────────┼─────────────────┼─────────────────┼─────────────────┤
//    │     │ lsft(lctl(f1))  │ lsft(lctl(f2))  │ lsft(lctl(f3))  │ lsft(lctl(f4))  │ lsft(lctl(f5))  │                                       │ lsft(lctl(f6))  │ lsft(lctl(f7))  │ lsft(lctl(f8))  │ lsft(lctl(f9))  │ lsft(lctl(f10)) │ lsft(lctl(f11)) │
//    ├─────┼─────────────────┼─────────────────┼─────────────────┼─────────────────┼─────────────────┤                                       ├─────────────────┼─────────────────┼─────────────────┼─────────────────┼─────────────────┼─────────────────┤
//    │     │ lsft(lctl(f12)) │ lsft(lctl(f13)) │ lctl(lalt(f16)) │ lctl(lalt(f17)) │ lsft(lctl(f16)) │                                       │ lsft(lctl(f17)) │ lsft(lctl(f18)) │ lsft(lctl(f19)) │ lctl(lalt(f18)) │ lctl(lalt(f12)) │ lctl(lalt(f13)) │
//    ├─────┼─────────────────┼─────────────────┼─────────────────┼─────────────────┼─────────────────┼─────┬─────┬─────┐   ┌─────┬─────┬─────┼─────────────────┼─────────────────┼─────────────────┼─────────────────┼─────────────────┼─────────────────┤
//    │     │ lctl(lalt(f1))  │ lctl(lalt(f2))  │ lctl(lalt(f3))  │ lctl(lalt(f4))  │ lctl(lalt(f5))  │     │     │     │   │     │     │     │ lctl(lalt(f6))  │ lctl(lalt(f7))  │ lctl(lalt(f8))  │ lctl(lalt(f9))  │ lctl(lalt(f10)) │ lctl(lalt(f11)) │
//    ├─────┼─────────────────┼─────────────────┼─────────────────┼─────────────────┼─────────────────┼─────┼─────┼─────┤   ├─────┼─────┼─────┼─────────────────┼─────────────────┼─────────────────┼─────────────────┼─────────────────┼─────────────────┤
//    │     │                 │                 │                 │                 │                 │     │     │     │   │     │     │     │                 │                 │                 │                 │                 │                 │
//    └─────┴─────────────────┴─────────────────┴─────────────────┴─────────────────┘                 └─────┴─────┴─────┘   └─────┴─────┴─────┘                 └─────────────────┴─────────────────┴─────────────────┴─────────────────┴─────────────────┘
  &trans   &trans            &trans            &trans            &trans                                                                                                          &trans            &trans            &trans            &trans            &trans
  &trans   &trans            &trans            &trans            &trans            &trans                                                                      &trans            &trans            &trans            &trans            &trans            &trans
  &trans   &kp LS(LC(F1))    &kp LS(LC(F2))    &kp LS(LC(F3))    &kp LS(LC(F4))    &kp LS(LC(F5))                                                              &kp LS(LC(F6))    &kp LS(LC(F7))    &kp LS(LC(F8))    &kp LS(LC(F9))    &kp LS(LC(F10))   &kp LS(LC(F11))
  &trans   &kp LS(LC(F12))   &kp LS(LC(F13))   &kp LC(LA(F16))   &kp LC(LA(F17))   &kp LS(LC(F16))                                                             &kp LS(LC(F17))   &kp LS(LC(F18))   &kp LS(LC(F19))   &kp LC(LA(F18))   &kp LC(LA(F12))   &kp LC(LA(F13))
  &trans   &kp LC(LA(F1))    &kp LC(LA(F2))    &kp LC(LA(F3))    &kp LC(LA(F4))    &kp LC(LA(F5))    &trans   &trans   &trans       &trans   &trans   &trans   &kp LC(LA(F6))    &kp LC(LA(F7))    &kp LC(LA(F8))    &kp LC(LA(F9))    &kp LC(LA(F10))   &kp LC(LA(F11))
  &trans   &trans            &trans            &trans            &trans                              &trans   &trans   &trans       &trans   &trans   &trans                     &trans            &trans            &trans            &trans            &trans
            >;
        };

        layer_Sesss {
            bindings = <
//    ┌─────┬─────┬─────┬─────────────────┬─────────────────┐                                                               ┌─────────────────┬─────────────────┬─────────────────┬─────────────────┬─────┐
//    │     │     │     │                 │                 │                                                               │                 │                 │                 │                 │     │
//    ├─────┼─────┼─────┼─────────────────┼─────────────────┼─────┐                                       ┌─────────────────┼─────────────────┼─────────────────┼─────────────────┼─────────────────┼─────┤
//    │     │     │     │                 │                 │     │                                       │                 │                 │                 │                 │                 │     │
//    ├─────┼─────┼─────┼─────────────────┼─────────────────┼─────┤                                       ├─────────────────┼─────────────────┼─────────────────┼─────────────────┼─────────────────┼─────┤
//    │     │     │     │ lctl(lgui(f12)) │ lctl(lgui(f13)) │     │                                       │ lctl(lgui(f16)) │ lctl(lgui(f17)) │ lctl(lgui(f18)) │ lctl(lalt(f19)) │ lctl(lgui(f1))  │     │
//    ├─────┼─────┼─────┼─────────────────┼─────────────────┼─────┤                                       ├─────────────────┼─────────────────┼─────────────────┼─────────────────┼─────────────────┼─────┤
//    │     │     │     │                 │                 │     │                                       │ lctl(lgui(f2))  │ lctl(lgui(f3))  │ lctl(lgui(f4))  │ lctl(lgui(f5))  │ lctl(lgui(f6))  │     │
//    ├─────┼─────┼─────┼─────────────────┼─────────────────┼─────┼─────┬─────┬─────┐   ┌─────┬─────┬─────┼─────────────────┼─────────────────┼─────────────────┼─────────────────┼─────────────────┼─────┤
//    │     │     │     │                 │                 │     │     │     │     │   │     │     │     │ lctl(lgui(f7))  │ lctl(lgui(f8))  │ lctl(lgui(f9))  │ lctl(lgui(f10)) │ lctl(lgui(f11)) │     │
//    ├─────┼─────┼─────┼─────────────────┼─────────────────┼─────┼─────┼─────┼─────┤   ├─────┼─────┼─────┼─────────────────┼─────────────────┼─────────────────┼─────────────────┼─────────────────┼─────┤
//    │     │     │     │                 │                 │     │     │     │     │   │     │     │     │                 │                 │                 │                 │                 │     │
//    └─────┴─────┴─────┴─────────────────┴─────────────────┘     └─────┴─────┴─────┘   └─────┴─────┴─────┘                 └─────────────────┴─────────────────┴─────────────────┴─────────────────┴─────┘
  &trans   &trans   &trans   &trans            &trans                                                                                                 &trans            &trans            &trans            &trans            &trans
  &trans   &trans   &trans   &trans            &trans            &trans                                                             &trans            &trans            &trans            &trans            &trans            &trans
  &trans   &trans   &trans   &kp LC(LG(F12))   &kp LC(LG(F13))   &trans                                                             &kp LC(LG(F16))   &kp LC(LG(F17))   &kp LC(LG(F18))   &kp LC(LA(F19))   &kp LC(LG(F1))    &trans
  &trans   &trans   &trans   &trans            &trans            &trans                                                             &kp LC(LG(F2))    &kp LC(LG(F3))    &kp LC(LG(F4))    &kp LC(LG(F5))    &kp LC(LG(F6))    &trans
  &trans   &trans   &trans   &trans            &trans            &trans   &trans   &trans   &trans       &trans   &trans   &trans   &kp LC(LG(F7))    &kp LC(LG(F8))    &kp LC(LG(F9))    &kp LC(LG(F10))   &kp LC(LG(F11))   &trans
  &trans   &trans   &trans   &trans            &trans                     &trans   &trans   &trans       &trans   &trans   &trans                     &trans            &trans            &trans            &trans            &trans
            >;
        };

        layer_Systm {
            bindings = <
//    ┌─────────┬────────────────┬─────┬──────┬──────────────────────────┐                                                                         ┌────────────────┬──────┬───────────────┬──────┬─────┐
//    │         │                │     │      │                          │                                                                         │                │      │               │      │     │
//    ├─────────┼────────────────┼─────┼──────┼──────────────────────────┼────────────────┐                                       ┌────────────────┼────────────────┼──────┼───────────────┼──────┼─────┤
//    │         │                │     │      │                          │                │                                       │                │                │      │               │      │     │
//    ├─────────┼────────────────┼─────┼──────┼──────────────────────────┼────────────────┤                                       ├────────────────┼────────────────┼──────┼───────────────┼──────┼─────┤
//    │         │ lgui(lalt(f2)) │     │ volu │ lt laltYER_Yabai lgui(=) │ lgui(lalt(f3)) │                                       │      prev      │      bri-      │ bri+ │     next      │ play │     │
//    ├─────────┼────────────────┼─────┼──────┼──────────────────────────┼────────────────┤                                       ├────────────────┼────────────────┼──────┼───────────────┼──────┼─────┤
//    │ lgui(W) │ lgui(lctl(Q))  │     │ vold │         lgui(-)          │ lgui(lalt(f4)) │                                       │ lgui(lsft([))  │ lgui(lalt(f6)) │      │ lgui(lsft(])) │      │     │
//    ├─────────┼────────────────┼─────┼──────┼──────────────────────────┼────────────────┼─────┬─────┬─────┐   ┌─────┬─────┬─────┼────────────────┼────────────────┼──────┼───────────────┼──────┼─────┤
//    │         │                │     │      │                          │                │     │     │     │   │     │     │     │ lgui(lalt(f5)) │ lgui(lalt(f7)) │      │               │      │     │
//    ├─────────┼────────────────┼─────┼──────┼──────────────────────────┼────────────────┼─────┼─────┼─────┤   ├─────┼─────┼─────┼────────────────┼────────────────┼──────┼───────────────┼──────┼─────┤
//    │         │                │     │      │                          │                │     │     │     │   │     │     │     │                │                │      │               │      │     │
//    └─────────┴────────────────┴─────┴──────┴──────────────────────────┘                └─────┴─────┴─────┘   └─────┴─────┴─────┘                └────────────────┴──────┴───────────────┴──────┴─────┘
  &trans      &trans           &trans   &trans         &trans                                                                                                                    &trans           &trans         &trans             &trans     &trans
  &trans      &trans           &trans   &trans         &trans                      &trans                                                                     &trans             &trans           &trans         &trans             &trans     &trans
  &trans      &kp LG(LA(F2))   &trans   &kp K_VOL_UP   &lt LAYER_Yabai LG(EQUAL)   &kp LG(LA(F3))                                                             &kp C_PREV         &kp C_BRI_DN     &kp C_BRI_UP   &kp C_NEXT         &kp C_PP   &trans
  &kp LG(W)   &kp LG(LC(Q))    &trans   &kp K_VOL_DN   &kp LG(MINUS)               &kp LG(LA(F4))                                                             &kp LG(LS(LBKT))   &kp LG(LA(F6))   &trans         &kp LG(LS(RBKT))   &trans     &trans
  &trans      &trans           &trans   &trans         &trans                      &trans           &trans   &trans   &trans       &trans   &trans   &trans   &kp LG(LA(F5))     &kp LG(LA(F7))   &trans         &trans             &trans     &trans
  &trans      &trans           &trans   &trans         &trans                                       &trans   &trans   &trans       &trans   &trans   &trans                      &trans           &trans         &trans             &trans     &trans
            >;
        };


        layer_Yabai {
            bindings = <
//    ┌─────┬─────┬─────┬─────┬───────────────────────┐                                                                     ┌───────────────────────┬───────────────────────┬───────────────────────┬─────┬─────┐
//    │     │     │     │     │                       │                                                                     │                       │                       │                       │     │     │
//    ├─────┼─────┼─────┼─────┼───────────────────────┼─────┐                                       ┌───────────────────────┼───────────────────────┼───────────────────────┼───────────────────────┼─────┼─────┤
//    │     │     │     │     │                       │     │                                       │                       │                       │                       │                       │     │     │
//    ├─────┼─────┼─────┼─────┼───────────────────────┼─────┤                                       ├───────────────────────┼───────────────────────┼───────────────────────┼───────────────────────┼─────┼─────┤
//    │     │     │     │     │ lsft(lalt(lctl(f10))) │     │                                       │ lsft(lalt(lctl(f11))) │ lsft(lalt(lctl(f12))) │ lsft(lalt(lctl(f13))) │ lsft(lalt(lctl(f16))) │     │     │
//    ├─────┼─────┼─────┼─────┼───────────────────────┼─────┤                                       ├───────────────────────┼───────────────────────┼───────────────────────┼───────────────────────┼─────┼─────┤
//    │     │     │     │     │                       │     │                                       │ lsft(lalt(lctl(f17))) │ lsft(lalt(lctl(f18))) │ lsft(lalt(lctl(f19))) │ lsft(lalt(lgui(f1)))  │     │     │
//    ├─────┼─────┼─────┼─────┼───────────────────────┼─────┼─────┬─────┬─────┐   ┌─────┬─────┬─────┼───────────────────────┼───────────────────────┼───────────────────────┼───────────────────────┼─────┼─────┤
//    │     │     │     │     │                       │     │     │     │     │   │     │     │     │ lsft(lalt(lgui(f2)))  │ lsft(lalt(lgui(f3)))  │ lsft(lalt(lgui(f4)))  │ lsft(lalt(lgui(f5)))  │     │     │
//    ├─────┼─────┼─────┼─────┼───────────────────────┼─────┼─────┼─────┼─────┤   ├─────┼─────┼─────┼───────────────────────┼───────────────────────┼───────────────────────┼───────────────────────┼─────┼─────┤
//    │     │     │     │     │                       │     │     │     │     │   │     │     │     │                       │                       │                       │                       │     │     │
//    └─────┴─────┴─────┴─────┴───────────────────────┘     └─────┴─────┴─────┘   └─────┴─────┴─────┘                       └───────────────────────┴───────────────────────┴───────────────────────┴─────┴─────┘
  &trans   &trans   &trans   &trans   &trans                                                                                                         &trans                &trans                &trans                &trans   &trans
  &trans   &trans   &trans   &trans   &trans                &trans                                                             &trans                &trans                &trans                &trans                &trans   &trans
  &trans   &trans   &trans   &trans   &kp LS(LA(LC(F10)))   &trans                                                             &kp LS(LA(LC(F11)))   &kp LS(LA(LC(F12)))   &kp LS(LA(LC(F13)))   &kp LS(LA(LC(F16)))   &trans   &trans
  &trans   &trans   &trans   &trans   &trans                &trans                                                             &kp LS(LA(LC(F17)))   &kp LS(LA(LC(F18)))   &kp LS(LA(LC(F19)))   &kp LS(LA(LG(F1)))    &trans   &trans
  &trans   &trans   &trans   &trans   &trans                &trans   &trans   &trans   &trans       &trans   &trans   &trans   &kp LS(LA(LG(F2)))    &kp LS(LA(LG(F3)))    &kp LS(LA(LG(F4)))    &kp LS(LA(LG(F5)))    &trans   &trans
  &trans   &trans   &trans   &trans   &trans                         &trans   &trans   &trans       &trans   &trans   &trans                         &trans                &trans                &trans                &trans   &trans
            >;
        };

        layer_Raycast {
            bindings = <
//    ┌─────┬─────┬─────┬─────────────────┬─────┐                                                               ┌─────────────────┬─────────────────┬─────────────────┬─────────────────┬─────┐
//    │     │     │     │                 │     │                                                               │                 │                 │                 │                 │     │
//    ├─────┼─────┼─────┼─────────────────┼─────┼─────┐                                       ┌─────────────────┼─────────────────┼─────────────────┼─────────────────┼─────────────────┼─────┤
//    │     │     │     │                 │     │     │                                       │                 │                 │                 │                 │                 │     │
//    ├─────┼─────┼─────┼─────────────────┼─────┼─────┤                                       ├─────────────────┼─────────────────┼─────────────────┼─────────────────┼─────────────────┼─────┤
//    │     │     │     │ lgui(lalt(f10)) │     │     │                                       │ lgui(lalt(f18)) │ lgui(lalt(f19)) │ lsft(lgui(f1))  │ lsft(lgui(f2))  │ lsft(lgui(f3))  │     │
//    ├─────┼─────┼─────┼─────────────────┼─────┼─────┤                                       ├─────────────────┼─────────────────┼─────────────────┼─────────────────┼─────────────────┼─────┤
//    │     │     │     │                 │     │     │                                       │ lgui(lalt(f11)) │ lgui(lalt(f12)) │ lgui(lalt(f13)) │ lgui(lalt(f16)) │ lgui(lalt(f17)) │     │
//    ├─────┼─────┼─────┼─────────────────┼─────┼─────┼─────┬─────┬─────┐   ┌─────┬─────┬─────┼─────────────────┼─────────────────┼─────────────────┼─────────────────┼─────────────────┼─────┤
//    │     │     │     │                 │     │     │     │     │     │   │     │     │     │                 │                 │                 │                 │                 │     │
//    ├─────┼─────┼─────┼─────────────────┼─────┼─────┼─────┼─────┼─────┤   ├─────┼─────┼─────┼─────────────────┼─────────────────┼─────────────────┼─────────────────┼─────────────────┼─────┤
//    │     │     │     │                 │     │     │     │     │     │   │     │     │     │                 │                 │                 │                 │                 │     │
//    └─────┴─────┴─────┴─────────────────┴─────┘     └─────┴─────┴─────┘   └─────┴─────┴─────┘                 └─────────────────┴─────────────────┴─────────────────┴─────────────────┴─────┘
  &trans   &trans   &trans   &trans            &trans                                                                                        &trans            &trans            &trans            &trans            &trans
  &trans   &trans   &trans   &trans            &trans   &trans                                                             &trans            &trans            &trans            &trans            &trans            &trans
  &trans   &trans   &trans   &kp LG(LA(F10))   &trans   &trans                                                             &kp LG(LA(F18))   &kp LG(LA(F19))   &kp LS(LG(F1))    &kp LS(LG(F2))    &kp LS(LG(F3))    &trans
  &trans   &trans   &trans   &trans            &trans   &trans                                                             &kp LG(LA(F11))   &kp LG(LA(F12))   &kp LG(LA(F13))   &kp LG(LA(F16))   &kp LG(LA(F17))   &trans
  &trans   &trans   &trans   &trans            &trans   &trans   &trans   &trans   &trans       &trans   &trans   &trans   &trans            &trans            &trans            &trans            &trans            &trans
  &trans   &trans   &trans   &trans            &trans            &trans   &trans   &trans       &trans   &trans   &trans                     &trans            &trans            &trans            &trans            &trans
            >;
        };

        layer_Letters {
            bindings = <
//    ┌─────┬─────┬─────┬────────────────┬─────┐                                                               ┌─────────────────┬─────────────────┬─────┬─────┬─────┐
//    │     │     │     │                │     │                                                               │                 │                 │     │     │     │
//    ├─────┼─────┼─────┼────────────────┼─────┼─────┐                                       ┌─────────────────┼─────────────────┼─────────────────┼─────┼─────┼─────┤
//    │     │     │     │                │     │     │                                       │                 │                 │                 │     │     │     │
//    ├─────┼─────┼─────┼────────────────┼─────┼─────┤                                       ├─────────────────┼─────────────────┼─────────────────┼─────┼─────┼─────┤
//    │     │     │     │                │     │     │                                       │ lsft(lgui(f5))  │ lsft(lgui(f6))  │ lsft(lgui(f7))  │     │     │     │
//    ├─────┼─────┼─────┼────────────────┼─────┼─────┤                                       ├─────────────────┼─────────────────┼─────────────────┼─────┼─────┼─────┤
//    │     │     │     │ lsft(lgui(f4)) │     │     │                                       │ lsft(lgui(f8))  │ lsft(lgui(f9))  │ lsft(lgui(f10)) │     │     │     │
//    ├─────┼─────┼─────┼────────────────┼─────┼─────┼─────┬─────┬─────┐   ┌─────┬─────┬─────┼─────────────────┼─────────────────┼─────────────────┼─────┼─────┼─────┤
//    │     │     │     │                │     │     │     │     │     │   │     │     │     │ lsft(lgui(f11)) │ lsft(lgui(f12)) │ lsft(lgui(f13)) │     │     │     │
//    ├─────┼─────┼─────┼────────────────┼─────┼─────┼─────┼─────┼─────┤   ├─────┼─────┼─────┼─────────────────┼─────────────────┼─────────────────┼─────┼─────┼─────┤
//    │     │     │     │                │     │     │     │     │     │   │     │     │     │                 │                 │                 │     │     │     │
//    └─────┴─────┴─────┴────────────────┴─────┘     └─────┴─────┴─────┘   └─────┴─────┴─────┘                 └─────────────────┴─────────────────┴─────┴─────┴─────┘
  &trans   &trans   &trans   &trans           &trans                                                                                        &trans            &trans            &trans   &trans   &trans
  &trans   &trans   &trans   &trans           &trans   &trans                                                             &trans            &trans            &trans            &trans   &trans   &trans
  &trans   &trans   &trans   &trans           &trans   &trans                                                             &kp LS(LG(F5))    &kp LS(LG(F6))    &kp LS(LG(F7))    &trans   &trans   &trans
  &trans   &trans   &trans   &kp LS(LG(F4))   &trans   &trans                                                             &kp LS(LG(F8))    &kp LS(LG(F9))    &kp LS(LG(F10))   &trans   &trans   &trans
  &trans   &trans   &trans   &trans           &trans   &trans   &trans   &trans   &trans       &trans   &trans   &trans   &kp LS(LG(F11))   &kp LS(LG(F12))   &kp LS(LG(F13))   &trans   &trans   &trans
  &trans   &trans   &trans   &trans           &trans            &trans   &trans   &trans       &trans   &trans   &trans                     &trans            &trans            &trans   &trans   &trans
            >;
        };

        layer_Obs {
            bindings = <
//    ┌─────┬─────────────────┬──────────────────────┬──────────────────────┬──────────────────────┐                                                                                     ┌──────────────────────┬──────────────────────┬──────────────────────┬──────────────────────┬─────┐
//    │     │                 │                      │                      │                      │                                                                                     │                      │                      │                      │                      │     │
//    ├─────┼─────────────────┼──────────────────────┼──────────────────────┼──────────────────────┼──────────────────────┐                                       ┌──────────────────────┼──────────────────────┼──────────────────────┼──────────────────────┼──────────────────────┼─────┤
//    │     │                 │                      │                      │                      │                      │                                       │                      │                      │                      │                      │                      │     │
//    ├─────┼─────────────────┼──────────────────────┼──────────────────────┼──────────────────────┼──────────────────────┤                                       ├──────────────────────┼──────────────────────┼──────────────────────┼──────────────────────┼──────────────────────┼─────┤
//    │     │ lsft(lalt(f1))  │    lsft(lalt(f2))    │    lsft(lalt(f3))    │    lsft(lalt(f4))    │    lsft(lalt(f5))    │                                       │    lsft(lalt(f6))    │    lsft(lalt(f7))    │    lsft(lalt(f8))    │                      │  mo laltYER_Obspos   │     │
//    ├─────┼─────────────────┼──────────────────────┼──────────────────────┼──────────────────────┼──────────────────────┤                                       ├──────────────────────┼──────────────────────┼──────────────────────┼──────────────────────┼──────────────────────┼─────┤
//    │     │ lsft(lalt(f11)) │   lsft(lalt(f12))    │   lsft(lalt(f13))    │   lsft(lalt(f16))    │   lsft(lalt(f17))    │                                       │   lsft(lalt(f18))    │   lsft(lalt(f19))    │   lsft(lgui(f16))    │   lsft(lgui(f17))    │   lsft(lgui(f18))    │     │
//    ├─────┼─────────────────┼──────────────────────┼──────────────────────┼──────────────────────┼──────────────────────┼─────┬─────┬─────┐   ┌─────┬─────┬─────┼──────────────────────┼──────────────────────┼──────────────────────┼──────────────────────┼──────────────────────┼─────┤
//    │     │ lsft(lgui(f19)) │ lsft(lalt(lctl(f1))) │ lsft(lalt(lctl(f2))) │ lsft(lalt(lctl(f3))) │ lsft(lalt(lctl(f4))) │     │     │     │   │     │     │     │ lsft(lalt(lctl(f5))) │ lsft(lalt(lctl(f6))) │ lsft(lalt(lctl(f7))) │ lsft(lalt(lctl(f8))) │ lsft(lalt(lctl(f9))) │     │
//    ├─────┼─────────────────┼──────────────────────┼──────────────────────┼──────────────────────┼──────────────────────┼─────┼─────┼─────┤   ├─────┼─────┼─────┼──────────────────────┼──────────────────────┼──────────────────────┼──────────────────────┼──────────────────────┼─────┤
//    │     │                 │                      │                      │                      │                      │     │     │     │   │     │     │     │                      │                      │                      │                      │                      │     │
//    └─────┴─────────────────┴──────────────────────┴──────────────────────┴──────────────────────┘                      └─────┴─────┴─────┘   └─────┴─────┴─────┘                      └──────────────────────┴──────────────────────┴──────────────────────┴──────────────────────┴─────┘
  &trans   &trans            &trans               &trans               &trans                                                                                                                   &trans               &trans               &trans               &trans               &trans
  &trans   &trans            &trans               &trans               &trans               &trans                                                                         &trans               &trans               &trans               &trans               &trans               &trans
  &trans   &kp LS(LA(F1))    &kp LS(LA(F2))       &kp LS(LA(F3))       &kp LS(LA(F4))       &kp LS(LA(F5))                                                                 &kp LS(LA(F6))       &kp LS(LA(F7))       &kp LS(LA(F8))       &trans               &mo LAYER_Obspos     &trans
  &trans   &kp LS(LA(F11))   &kp LS(LA(F12))      &kp LS(LA(F13))      &kp LS(LA(F16))      &kp LS(LA(F17))                                                                &kp LS(LA(F18))      &kp LS(LA(F19))      &kp LS(LG(F16))      &kp LS(LG(F17))      &kp LS(LG(F18))      &trans
  &trans   &kp LS(LG(F19))   &kp LS(LA(LC(F1)))   &kp LS(LA(LC(F2)))   &kp LS(LA(LC(F3)))   &kp LS(LA(LC(F4)))   &trans   &trans   &trans       &trans   &trans   &trans   &kp LS(LA(LC(F5)))   &kp LS(LA(LC(F6)))   &kp LS(LA(LC(F7)))   &kp LS(LA(LC(F8)))   &kp LS(LA(LC(F9)))   &trans
  &trans   &trans            &trans               &trans               &trans                                    &trans   &trans   &trans       &trans   &trans   &trans                        &trans               &trans               &trans               &trans               &trans
            >;
        };

        layer_Bluetooth {
            bindings = <
//    ┌─────┬─────┬─────┬─────┬─────┐                                                      ┌──────────┬──────────┬──────────┬──────────┬──────────┐
//    │     │     │     │     │     │                                                      │          │          │          │          │          │
//    ├─────┼─────┼─────┼─────┼─────┼─────┐                                       ┌────────┼──────────┼──────────┼──────────┼──────────┼──────────┤
//    │     │     │     │     │     │     │                                       │        │          │          │          │          │          │
//    ├─────┼─────┼─────┼─────┼─────┼─────┤                                       ├────────┼──────────┼──────────┼──────────┼──────────┼──────────┤
//    │     │     │     │     │     │     │                                       │        │   to 0   │   to 1   │          │          │          │
//    ├─────┼─────┼─────┼─────┼─────┼─────┤                                       ├────────┼──────────┼──────────┼──────────┼──────────┼──────────┤
//    │     │     │     │     │     │     │                                       │ bt_clr │ bt_sel 0 │ bt_sel 1 │ bt_sel 2 │ bt_sel 3 │ bt_sel 4 │
//    ├─────┼─────┼─────┼─────┼─────┼─────┼─────┬─────┬─────┐   ┌─────┬─────┬─────┼────────┼──────────┼──────────┼──────────┼──────────┼──────────┤
//    │     │     │     │     │     │     │     │     │     │   │     │     │     │        │          │          │          │          │          │
//    ├─────┼─────┼─────┼─────┼─────┼─────┼─────┼─────┼─────┤   ├─────┼─────┼─────┼────────┼──────────┼──────────┼──────────┼──────────┼──────────┤
//    │     │     │     │     │     │     │     │     │     │   │     │     │     │        │          │          │          │          │          │
//    └─────┴─────┴─────┴─────┴─────┘     └─────┴─────┴─────┘   └─────┴─────┴─────┘        └──────────┴──────────┴──────────┴──────────┴──────────┘
  &trans   &trans   &trans   &trans   &trans                                                                                 &trans         &trans         &trans         &trans         &trans
  &trans   &trans   &trans   &trans   &trans   &trans                                                           &trans       &trans         &trans         &trans         &trans         &trans
  &trans   &trans   &trans   &trans   &trans   &trans                                                           &trans       &to 0          &to 1          &trans         &trans         &trans
  &trans   &trans   &trans   &trans   &trans   &trans                                                           &bt BT_CLR   &bt BT_SEL 0   &bt BT_SEL 1   &bt BT_SEL 2   &bt BT_SEL 3   &bt BT_SEL 4
  &trans   &trans   &trans   &trans   &trans   &trans   &none    &none    &none       &none   &none    &none    &trans       &trans         &trans         &trans         &trans         &trans
  &trans   &trans   &trans   &trans   &trans            &trans   &trans   &none       &none   &trans   &trans                &trans         &trans         &trans         &trans         &trans
            >;
        };

        layer_Obspos {
            bindings = <
//    ┌─────┬────────────────┬─────────────────┬──────────────────────┬──────────────────────┐                                                   ┌─────┬─────┬─────┬─────┬─────┐
//    │     │                │                 │                      │                      │                                                   │     │     │     │     │     │
//    ├─────┼────────────────┼─────────────────┼──────────────────────┼──────────────────────┼─────┐                                       ┌─────┼─────┼─────┼─────┼─────┼─────┤
//    │     │                │                 │                      │                      │     │                                       │     │     │     │     │     │     │
//    ├─────┼────────────────┼─────────────────┼──────────────────────┼──────────────────────┼─────┤                                       ├─────┼─────┼─────┼─────┼─────┼─────┤
//    │     │                │                 │                      │                      │     │                                       │     │     │     │     │     │     │
//    ├─────┼────────────────┼─────────────────┼──────────────────────┼──────────────────────┼─────┤                                       ├─────┼─────┼─────┼─────┼─────┼─────┤
//    │     │ lsft(lalt(f9)) │ lsft(lalt(f10)) │ lsft(lalt(lgui(f8))) │ lsft(lalt(lgui(f9))) │     │                                       │     │     │     │     │     │     │
//    ├─────┼────────────────┼─────────────────┼──────────────────────┼──────────────────────┼─────┼─────┬─────┬─────┐   ┌─────┬─────┬─────┼─────┼─────┼─────┼─────┼─────┼─────┤
//    │     │                │                 │                      │                      │     │     │     │     │   │     │     │     │     │     │     │     │     │     │
//    ├─────┼────────────────┼─────────────────┼──────────────────────┼──────────────────────┼─────┼─────┼─────┼─────┤   ├─────┼─────┼─────┼─────┼─────┼─────┼─────┼─────┼─────┤
//    │     │                │                 │                      │                      │     │     │     │     │   │     │     │     │     │     │     │     │     │     │
//    └─────┴────────────────┴─────────────────┴──────────────────────┴──────────────────────┘     └─────┴─────┴─────┘   └─────┴─────┴─────┘     └─────┴─────┴─────┴─────┴─────┘
  &trans   &trans           &trans            &trans               &trans                                                                                         &trans   &trans   &trans   &trans   &trans
  &trans   &trans           &trans            &trans               &trans               &trans                                                           &trans   &trans   &trans   &trans   &trans   &trans
  &trans   &trans           &trans            &trans               &trans               &trans                                                           &trans   &trans   &trans   &trans   &trans   &trans
  &trans   &kp LS(LA(F9))   &kp LS(LA(F10))   &kp LS(LA(LG(F8)))   &kp LS(LA(LG(F9)))   &trans                                                           &trans   &trans   &trans   &trans   &trans   &trans
  &trans   &trans           &trans            &trans               &trans               &trans   &none    &none    &none       &none   &none    &none    &trans   &trans   &trans   &trans   &trans   &trans
  &trans   &trans           &trans            &trans               &trans                        &trans   &trans   &none       &none   &trans   &trans            &trans   &trans   &trans   &trans   &trans
            >;
        };

        layer_Work {
            bindings = <
//    ┌─────┬─────┬─────┬─────┬───────────────────────┐                                                   ┌───────────────────────┬───────────────────────┬───────────────────────┬───────────────────────┬─────┐
//    │     │     │     │     │                       │                                                   │                       │                       │                       │                       │     │
//    ├─────┼─────┼─────┼─────┼───────────────────────┼─────┐                                       ┌─────┼───────────────────────┼───────────────────────┼───────────────────────┼───────────────────────┼─────┤
//    │     │     │     │     │                       │     │                                       │     │                       │                       │                       │                       │     │
//    ├─────┼─────┼─────┼─────┼───────────────────────┼─────┤                                       ├─────┼───────────────────────┼───────────────────────┼───────────────────────┼───────────────────────┼─────┤
//    │     │     │     │     │                       │     │                                       │     │                       │                       │ lsft(lalt(lgui(f12))) │                       │     │
//    ├─────┼─────┼─────┼─────┼───────────────────────┼─────┤                                       ├─────┼───────────────────────┼───────────────────────┼───────────────────────┼───────────────────────┼─────┤
//    │     │     │     │     │ lsft(lalt(lgui(f18))) │     │                                       │     │ lsft(lalt(lgui(f16))) │ lsft(lalt(lgui(f11))) │                       │ lsft(lalt(lgui(f17))) │     │
//    ├─────┼─────┼─────┼─────┼───────────────────────┼─────┼─────┬─────┬─────┐   ┌─────┬─────┬─────┼─────┼───────────────────────┼───────────────────────┼───────────────────────┼───────────────────────┼─────┤
//    │     │     │     │     │                       │     │     │     │     │   │     │     │     │     │ lsft(lalt(lgui(f13))) │                       │                       │                       │     │
//    ├─────┼─────┼─────┼─────┼───────────────────────┼─────┼─────┼─────┼─────┤   ├─────┼─────┼─────┼─────┼───────────────────────┼───────────────────────┼───────────────────────┼───────────────────────┼─────┤
//    │     │     │     │     │                       │     │     │     │     │   │     │     │     │     │                       │                       │                       │                       │     │
//    └─────┴─────┴─────┴─────┴───────────────────────┘     └─────┴─────┴─────┘   └─────┴─────┴─────┘     └───────────────────────┴───────────────────────┴───────────────────────┴───────────────────────┴─────┘
  &trans   &trans   &trans   &trans   &trans                                                                                          &trans                &trans                &trans                &trans                &trans
  &trans   &trans   &trans   &trans   &trans                &trans                                                           &trans   &trans                &trans                &trans                &trans                &trans
  &trans   &trans   &trans   &trans   &trans                &trans                                                           &trans   &trans                &trans                &kp LS(LA(LG(F12)))   &trans                &trans
  &trans   &trans   &trans   &trans   &kp LS(LA(LG(F18)))   &trans                                                           &trans   &kp LS(LA(LG(F16)))   &kp LS(LA(LG(F11)))   &trans                &kp LS(LA(LG(F17)))   &trans
  &trans   &trans   &trans   &trans   &trans                &trans   &none    &none    &none       &none   &none    &none    &trans   &kp LS(LA(LG(F13)))   &trans                &trans                &trans                &trans
  &trans   &trans   &trans   &trans   &trans                         &trans   &trans   &none       &none   &trans   &trans            &trans                &trans                &trans                &trans                &trans
            >;
        };

        /* layer_Template { */
        /*     bindings = < */
        /*       &trans                     &trans                     &trans                    &trans                   &trans                                                                                                                    &trans                  &trans                 &trans                  &trans                    &trans */
        /*       &trans                     &trans                     &trans                    &trans                   &trans                &trans                                                                       &trans                 &trans                  &trans                 &trans                  &trans                    &trans */
        /*       &trans                     &trans                     &trans                    &trans                   &trans                &trans                                                                       &trans                 &trans                  &trans                 &trans                  &trans                    &trans */
        /*       &trans                     &trans                     &trans                    &trans                   &trans                &trans                                                                       &trans                 &trans                  &trans                 &trans                  &trans                    &trans */
        /*       &trans                     &trans                     &trans                    &trans                   &trans                &trans                 &trans  &trans  &trans  &trans  &trans  &trans        &trans                 &trans                  &trans                 &trans                  &trans                    &trans */
        /*       &trans                     &trans                     &trans                    &trans                   &trans                                       &trans  &trans  &trans  &trans  &trans  &trans                               &trans                  &trans                 &trans                  &trans                    &trans */
        /*     >; */
        /* }; */

    };
};
